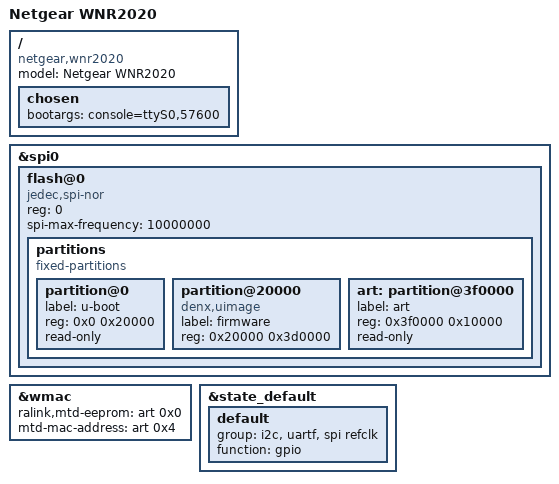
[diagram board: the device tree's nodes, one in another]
/dts-v1/;

#include <dt-bindings/gpio/gpio.h>
#include <dt-bindings/input/input.h>

#include "mt7620a.dtsi"

/ {
	compatible = "netgear,wnr2020", "ralink,mt7620a-soc";
	model = "Netgear WNR2020";

	chosen {
		bootargs = "console=ttyS0,57600";
	};

	//keys {
	//	compatible = "gpio-keys";
	//	reset {
	//		label = "reset";
	//		gpios = <&gpio0 1 GPIO_ACTIVE_LOW>;
	//		linux,code = <KEY_RESTART>;
	//	};
	//};

	//leds {
	//	compatible = "gpio-leds";

	//	power_g {
	//		label = "wn3000rp-v3:green:power";
	//		gpios = <&gpio0 9 GPIO_ACTIVE_LOW>;
	//		default-state = "on";
	//	};

	//	power_r {
	//		label = "wn3000rp-v3:red:power";
	//		gpios = <&gpio0 11 GPIO_ACTIVE_LOW>;
	//	};

	//	client_g {
	//		label = "wn3000rp-v3:green:client";
	//		gpios = <&gpio0 13 GPIO_ACTIVE_LOW>;
	//	};

	//	client_r {
	//		label = "wn3000rp-v3:red:client";
	//		gpios = <&gpio0 10 GPIO_ACTIVE_LOW>;
	//	};

	//	router_g {
	//		label = "wn3000rp-v3:green:router";
	//		gpios = <&gpio0 12 GPIO_ACTIVE_LOW>;
	//	};

	//	router_r {
	//		label = "wn3000rp-v3:red:router";
	//		gpios = <&gpio0 14 GPIO_ACTIVE_LOW>;
	//	};

	//};
};

&spi0 {
	status = "okay";

	flash@0 {
		compatible = "jedec,spi-nor";
		reg = <0>;
		spi-max-frequency = <10000000>;

		partitions {
			compatible = "fixed-partitions";
			#address-cells = <1>;
			#size-cells = <1>;

			partition@0 {
				label = "u-boot";
				reg = <0x0 0x20000>;
				read-only;
			};

			partition@20000 {
				compatible = "denx,uimage";
				label = "firmware";
				reg = <0x20000 0x3d0000>;
			};

			art: partition@3f0000 {
				label = "art";
				reg = <0x3f0000 0x10000>;
				read-only;
			};
		};
	};
};

//&ethernet {
//	mtd-mac-address = <&art 0x0>;
//};

&wmac {
	ralink,mtd-eeprom = <&art 0x0>;
	mtd-mac-address = <&art 0x4>;
};

&state_default {
	default {
		group = "i2c", "uartf", "spi refclk";
		function = "gpio";
	};
};
